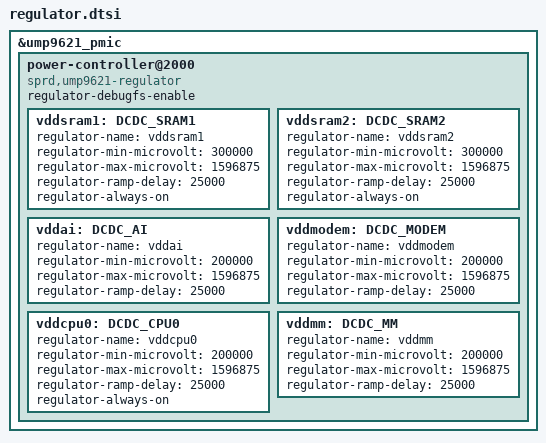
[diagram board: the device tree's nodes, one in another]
/*
 * UNISOC UMP9621 PMIC regulator dts file
 *
 * Copyright (C) 2020, UNISOC Communications Inc.
 *
 * SPDX-License-Identifier: (GPL-2.0+ OR MIT)
 */
&ump9621_pmic {
		power-controller@2000 {
		compatible = "sprd,ump9621-regulator";
		regulator-debugfs-enable;

		vddsram1: DCDC_SRAM1 {
			regulator-name = "vddsram1";
			regulator-min-microvolt = <300000>;
			regulator-max-microvolt = <1596875>;
			regulator-ramp-delay = <25000>;
			regulator-always-on;
		};

		vddsram2: DCDC_SRAM2 {
			regulator-name = "vddsram2";
			regulator-min-microvolt = <300000>;
			regulator-max-microvolt = <1596875>;
			regulator-ramp-delay = <25000>;
			regulator-always-on;
		};

		vddai: DCDC_AI {
			regulator-name = "vddai";
			regulator-min-microvolt = <200000>;
			regulator-max-microvolt = <1596875>;
			regulator-ramp-delay = <25000>;
		};

		vddmodem: DCDC_MODEM {
			regulator-name = "vddmodem";
			regulator-min-microvolt = <200000>;
			regulator-max-microvolt = <1596875>;
			regulator-ramp-delay = <25000>;
		};

		vddcpu0: DCDC_CPU0 {
			regulator-name = "vddcpu0";
			regulator-min-microvolt = <200000>;
			regulator-max-microvolt = <1596875>;
			regulator-ramp-delay = <25000>;
			regulator-always-on;
		};

		vddmm: DCDC_MM {
			regulator-name = "vddmm";
			regulator-min-microvolt = <200000>;
			regulator-max-microvolt = <1596875>;
			regulator-ramp-delay = <25000>;
		};
	};
};
